AUTOSAR XML (schema 00051)
package /Components
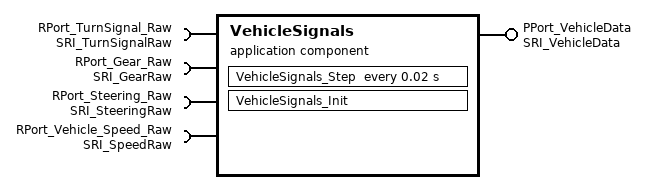
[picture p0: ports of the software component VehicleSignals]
  application sw component type VehicleSignals
    4 x require port:
      RPort_TurnSignal_Raw: nonqueued-receiver-com-spec{data-element=Raw_turn_sig, init-value=0}, required-interface=SRI_TurnSignalRaw
      RPort_Gear_Raw: nonqueued-receiver-com-spec{data-element=Gear_Raw, init-value=0}, required-interface=SRI_GearRaw
      RPort_Steering_Raw: nonqueued-receiver-com-spec{data-element=Raw_steering, init-value=0}, required-interface=SRI_SteeringRaw
      RPort_Vehicle_Speed_Raw: nonqueued-receiver-com-spec{data-element=Vehicle_Speed_Raw, init-value=0}, required-interface=SRI_SpeedRaw
    provide port PPort_VehicleData: provided-interface=SRI_VehicleData
      provided-com-specs:
        data-element=Steering_Status, init-value=SIGNAL_OK
        data-element=Steering_Angle, init-value=0
        data-element=Gear_Status, init-value=SIGNAL_OK
        data-element=Gear, init-value=GEAR_PARK
        data-element=TurnSignal_Status, init-value=SIGNAL_OK
        data-element=TurnSignal, init-value=TURN_OFF
        data-element=Vehicle_Speed, init-value=0
        data-element=Speed_Status, init-value=SIGNAL_OK
    behavior VehicleSignals_IB: data-type-mapping=bsdDataTypeMappingsSet, handle-termination-and-restart=NO-SUPPORT
      timing event TE_20ms_VehicleSignals: start-on-event=VehicleSignals_Step, period=0.02
      runnable VehicleSignals_Init
      runnable VehicleSignals_Step
        data-read-access:
          4 x access:
            IN_RPort_Gear_Raw_Gear_Raw: accessed-variable=RPort_Gear_Raw.Gear_Raw
            IN_RPort_Steering_Raw_Raw_steering: accessed-variable=RPort_Steering_Raw.Raw_steering
            IN_RPort_TurnSignal_Raw_Raw_turn_sig: accessed-variable=RPort_TurnSignal_Raw.Raw_turn_sig
            IN_RPort_Vehicle_Speed_Raw_Vehicle_Speed_Raw: accessed-variable=RPort_Vehicle_Speed_Raw.Vehicle_Speed_Raw
        data-write-access:
          8 x access:
            OUT_PPort_VehicleData_Steering_Status: accessed-variable=PPort_VehicleData.Steering_Status
            OUT_PPort_VehicleData_Steering_Angle: accessed-variable=PPort_VehicleData.Steering_Angle
            OUT_PPort_VehicleData_Gear_Status: accessed-variable=PPort_VehicleData.Gear_Status
            OUT_PPort_VehicleData_Gear: accessed-variable=PPort_VehicleData.Gear
            OUT_PPort_VehicleData_TurnSignal_Status: accessed-variable=PPort_VehicleData.TurnSignal_Status
            OUT_PPort_VehicleData_TurnSignal: accessed-variable=PPort_VehicleData.TurnSignal
            OUT_PPort_VehicleData_Vehicle_Speed: accessed-variable=PPort_VehicleData.Vehicle_Speed
            OUT_PPort_VehicleData_Speed_Status: accessed-variable=PPort_VehicleData.Speed_Status
